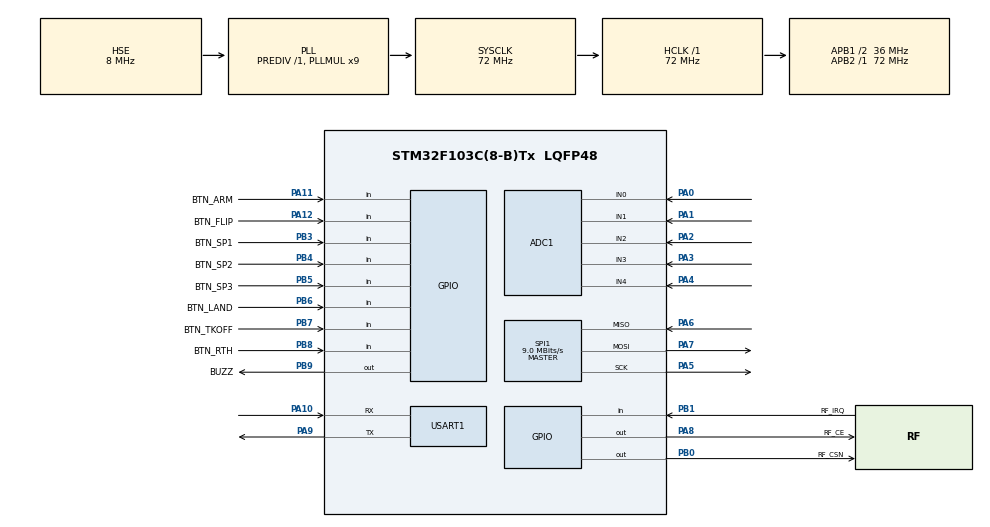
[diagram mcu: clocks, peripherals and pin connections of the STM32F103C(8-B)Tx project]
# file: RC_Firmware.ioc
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ADC1.Channel-0\#ChannelRegularConversion=ADC_CHANNEL_0
ADC1.ContinuousConvMode=ENABLE
ADC1.NbrOfConversionFlag=1
ADC1.Rank-0\#ChannelRegularConversion=1
ADC1.SamplingTime-0\#ChannelRegularConversion=ADC_SAMPLETIME_1CYCLE_5
ADC1.master=1
Dma.ADC1.0.Direction=DMA_PERIPH_TO_MEMORY
Dma.ADC1.0.Instance=DMA1_Channel1
Dma.ADC1.0.MemDataAlignment=DMA_MDATAALIGN_HALFWORD
Dma.ADC1.0.MemInc=DMA_MINC_ENABLE
Dma.ADC1.0.Mode=DMA_NORMAL
Dma.ADC1.0.PeriphDataAlignment=DMA_PDATAALIGN_HALFWORD
Dma.ADC1.0.PeriphInc=DMA_PINC_DISABLE
Dma.ADC1.0.Priority=DMA_PRIORITY_LOW
Dma.Request0=ADC1
Mcu.Family=STM32F1
Mcu.Name=STM32F103C(8-B)Tx
Mcu.Package=LQFP48
NVIC.DMA1_Channel1_IRQn=true\:0\:0\:false\:false\:true\:false\:true\:true
NVIC.PriorityGroup=NVIC_PRIORITYGROUP_4
PA0-WKUP.Signal=ADCx_IN0
PA1.Signal=ADCx_IN1
PA10.Mode=Asynchronous
PA10.Signal=USART1_RX
PA11.GPIO_Label=BTN_ARM
PA11.Signal=GPIO_Input
PA12.GPIO_Label=BTN_FLIP
PA12.Signal=GPIO_Input
PA13.Mode=Serial_Wire
PA13.Signal=SYS_JTMS-SWDIO
PA14.Mode=Serial_Wire
PA14.Signal=SYS_JTCK-SWCLK
PA2.Signal=ADCx_IN2
PA3.Signal=ADCx_IN3
PA4.Signal=ADCx_IN4
PA5.Mode=Full_Duplex_Master
PA5.Signal=SPI1_SCK
PA6.Mode=Full_Duplex_Master
PA6.Signal=SPI1_MISO
PA7.Mode=Full_Duplex_Master
PA7.Signal=SPI1_MOSI
PA8.GPIO_Label=RF_CE
PA8.Signal=GPIO_Output
PA9.Mode=Asynchronous
PA9.Signal=USART1_TX
PB0.GPIO_Label=RF_CSN
PB0.Signal=GPIO_Output
PB1.GPIO_Label=RF_IRQ
PB1.Signal=GPIO_Input
PB3.GPIO_Label=BTN_SP1
PB3.Signal=GPIO_Input
PB4.GPIO_Label=BTN_SP2
PB4.Signal=GPIO_Input
PB5.GPIO_Label=BTN_SP3
PB5.Signal=GPIO_Input
PB6.GPIO_Label=BTN_LAND
PB6.Signal=GPIO_Input
PB7.GPIO_Label=BTN_TKOFF
PB7.Signal=GPIO_Input
PB8.GPIO_Label=BTN_RTH
PB8.Signal=GPIO_Input
PB9.GPIO_Label=BUZZ
PB9.Signal=GPIO_Output
PD0-OSC_IN.Mode=HSE-External-Oscillator
PD0-OSC_IN.Signal=RCC_OSC_IN
PD1-OSC_OUT.Mode=HSE-External-Oscillator
PD1-OSC_OUT.Signal=RCC_OSC_OUT
ProjectManager.HeapSize=0x200
ProjectManager.StackSize=0x400
ProjectManager.TargetToolchain=STM32CubeIDE
RCC.ADCPresc=RCC_ADCPCLK2_DIV6
RCC.AHBFreq_Value=72000000
RCC.APB1CLKDivider=RCC_HCLK_DIV2
RCC.APB1Freq_Value=36000000
RCC.APB1TimFreq_Value=72000000
RCC.APB2Freq_Value=72000000
RCC.APB2TimFreq_Value=72000000
RCC.HCLKFreq_Value=72000000
RCC.PLLMUL=RCC_PLL_MUL9
RCC.PLLSourceVirtual=RCC_PLLSOURCE_HSE
RCC.SYSCLKFreq_VALUE=72000000
RCC.SYSCLKSource=RCC_SYSCLKSOURCE_PLLCLK
RCC.USBFreq_Value=72000000
SH.ADCx_IN0.0=ADC1_IN0,IN0
SH.ADCx_IN1.0=ADC1_IN1,IN1
SH.ADCx_IN2.0=ADC1_IN2,IN2
SH.ADCx_IN3.0=ADC1_IN3,IN3
SH.ADCx_IN4.0=ADC1_IN4,IN4
SPI1.BaudRatePrescaler=SPI_BAUDRATEPRESCALER_8
SPI1.CalculateBaudRate=9.0 MBits/s
SPI1.Direction=SPI_DIRECTION_2LINES
SPI1.Mode=SPI_MODE_MASTER
SPI1.VirtualType=VM_MASTER
USART1.VirtualMode=VM_ASYNC
board=custom

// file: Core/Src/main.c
/* USER CODE BEGIN Header */
/**
  ******************************************************************************
  * @file           : main.c
  * @brief          : Main program body
  ******************************************************************************
  * @attention
  *
  * Copyright (c) 2026 STMicroelectronics.
  * All rights reserved.
  *
  * This software is licensed under terms that can be found in the LICENSE file
  * in the root directory of this software component.
  * If no LICENSE file comes with this software, it is provided AS-IS.
  *
  ******************************************************************************
  */
/* USER CODE END Header */
#include "main.h"

/* USER CODE BEGIN Includes */
#include "bk2423.h"
#include "rc_input.h"
#include "rc_packet.h"
/* USER CODE END Includes */

ADC_HandleTypeDef hadc1;
DMA_HandleTypeDef hdma_adc1;

SPI_HandleTypeDef hspi1;

UART_HandleTypeDef huart1;

/* USER CODE BEGIN PV */
static NRF_Handle nrf = { &hspi1, RF_CE_GPIO_Port, RF_CE_Pin,
                                   RF_CSN_GPIO_Port, RF_CSN_Pin };
static uint16_t   adc_raw[5];   /* DMA fills: [0]=thr [1]=yaw [2]=pit [3]=rol [4]=vbat */
static RC_Packet  pkt;
/* USER CODE END PV */

void SystemClock_Config(void);
static void MX_GPIO_Init(void);
static void MX_DMA_Init(void);
static void MX_ADC1_Init(void);
static void MX_SPI1_Init(void);
static void MX_USART1_UART_Init(void);

int main(void)
{

  /* MCU Configuration--------------------------------------------------------*/

  /* Reset of all peripherals, Initializes the Flash interface and the Systick. */
  HAL_Init();

  /* Configure the system clock */
  SystemClock_Config();

  /* Initialize all configured peripherals */
  MX_GPIO_Init();
  MX_DMA_Init();
  MX_ADC1_Init();
  MX_SPI1_Init();
  MX_USART1_UART_Init();
  /* USER CODE BEGIN 2 */
  HAL_ADC_Start_DMA(&hadc1, (uint32_t*)adc_raw, 5);
  NRF_Init_TX(&nrf);
  /* USER CODE END 2 */

  /* Infinite loop */
  /* USER CODE BEGIN WHILE */
  while (1) {
      RC_Input_Update(&pkt, adc_raw);
      NRF_Send(&nrf, &pkt, sizeof(pkt));
      HAL_Delay(10);   /* 100 Hz transmit rate */
  /* USER CODE END WHILE */
  }

  }
}

void SystemClock_Config(void)
{
  RCC_OscInitTypeDef RCC_OscInitStruct = {0};
  RCC_ClkInitTypeDef RCC_ClkInitStruct = {0};
  RCC_PeriphCLKInitTypeDef PeriphClkInit = {0};

  /** Initializes the RCC Oscillators according to the specified parameters
  * in the RCC_OscInitTypeDef structure.
  */
  RCC_OscInitStruct.OscillatorType = RCC_OSCILLATORTYPE_HSE;
  RCC_OscInitStruct.HSEState = RCC_HSE_ON;
  RCC_OscInitStruct.HSEPredivValue = RCC_HSE_PREDIV_DIV1;
  RCC_OscInitStruct.HSIState = RCC_HSI_ON;
  RCC_OscInitStruct.PLL.PLLState = RCC_PLL_ON;
  RCC_OscInitStruct.PLL.PLLSource = RCC_PLLSOURCE_HSE;
  RCC_OscInitStruct.PLL.PLLMUL = RCC_PLL_MUL9;
  if (HAL_RCC_OscConfig(&RCC_OscInitStruct) != HAL_OK)
  {
    Error_Handler();
  }

  /** Initializes the CPU, AHB and APB buses clocks
  */
  RCC_ClkInitStruct.ClockType = RCC_CLOCKTYPE_HCLK|RCC_CLOCKTYPE_SYSCLK
                              |RCC_CLOCKTYPE_PCLK1|RCC_CLOCKTYPE_PCLK2;
  RCC_ClkInitStruct.SYSCLKSource = RCC_SYSCLKSOURCE_PLLCLK;
  RCC_ClkInitStruct.AHBCLKDivider = RCC_SYSCLK_DIV1;
  RCC_ClkInitStruct.APB1CLKDivider = RCC_HCLK_DIV2;
  RCC_ClkInitStruct.APB2CLKDivider = RCC_HCLK_DIV1;

  if (HAL_RCC_ClockConfig(&RCC_ClkInitStruct, FLASH_LATENCY_2) != HAL_OK)
  {
    Error_Handler();
  }
  PeriphClkInit.PeriphClockSelection = RCC_PERIPHCLK_ADC;
  PeriphClkInit.AdcClockSelection = RCC_ADCPCLK2_DIV6;
  if (HAL_RCCEx_PeriphCLKConfig(&PeriphClkInit) != HAL_OK)
  {
    Error_Handler();
  }
}

static void MX_ADC1_Init(void)
{

  ADC_ChannelConfTypeDef sConfig = {0};

  /** Common config
  */
  hadc1.Instance = ADC1;
  hadc1.Init.ScanConvMode = ADC_SCAN_DISABLE;
  hadc1.Init.ContinuousConvMode = ENABLE;
  hadc1.Init.DiscontinuousConvMode = DISABLE;
  hadc1.Init.ExternalTrigConv = ADC_SOFTWARE_START;
  hadc1.Init.DataAlign = ADC_DATAALIGN_RIGHT;
  hadc1.Init.NbrOfConversion = 1;
  if (HAL_ADC_Init(&hadc1) != HAL_OK)
  {
    Error_Handler();
  }

  /** Configure Regular Channel
  */
  sConfig.Channel = ADC_CHANNEL_0;
  sConfig.Rank = ADC_REGULAR_RANK_1;
  sConfig.SamplingTime = ADC_SAMPLETIME_1CYCLE_5;
  if (HAL_ADC_ConfigChannel(&hadc1, &sConfig) != HAL_OK)
  {
    Error_Handler();
  }

}

static void MX_SPI1_Init(void)
{

  /* SPI1 parameter configuration*/
  hspi1.Instance = SPI1;
  hspi1.Init.Mode = SPI_MODE_MASTER;
  hspi1.Init.Direction = SPI_DIRECTION_2LINES;
  hspi1.Init.DataSize = SPI_DATASIZE_8BIT;
  hspi1.Init.CLKPolarity = SPI_POLARITY_LOW;
  hspi1.Init.CLKPhase = SPI_PHASE_1EDGE;
  hspi1.Init.NSS = SPI_NSS_SOFT;
  hspi1.Init.BaudRatePrescaler = SPI_BAUDRATEPRESCALER_8;
  hspi1.Init.FirstBit = SPI_FIRSTBIT_MSB;
  hspi1.Init.TIMode = SPI_TIMODE_DISABLE;
  hspi1.Init.CRCCalculation = SPI_CRCCALCULATION_DISABLE;
  hspi1.Init.CRCPolynomial = 10;
  if (HAL_SPI_Init(&hspi1) != HAL_OK)
  {
    Error_Handler();
  }

}

static void MX_USART1_UART_Init(void)
{

  huart1.Instance = USART1;
  huart1.Init.BaudRate = 115200;
  huart1.Init.WordLength = UART_WORDLENGTH_8B;
  huart1.Init.StopBits = UART_STOPBITS_1;
  huart1.Init.Parity = UART_PARITY_NONE;
  huart1.Init.Mode = UART_MODE_TX_RX;
  huart1.Init.HwFlowCtl = UART_HWCONTROL_NONE;
  huart1.Init.OverSampling = UART_OVERSAMPLING_16;
  if (HAL_UART_Init(&huart1) != HAL_OK)
  {
    Error_Handler();
  }

}

static void MX_DMA_Init(void)
{

  /* DMA controller clock enable */
  __HAL_RCC_DMA1_CLK_ENABLE();

  /* DMA interrupt init */
  /* DMA1_Channel1_IRQn interrupt configuration */
  HAL_NVIC_SetPriority(DMA1_Channel1_IRQn, 0, 0);
  HAL_NVIC_EnableIRQ(DMA1_Channel1_IRQn);

}

static void MX_GPIO_Init(void)
{
  GPIO_InitTypeDef GPIO_InitStruct = {0};

  /* GPIO Ports Clock Enable */
  __HAL_RCC_GPIOD_CLK_ENABLE();
  __HAL_RCC_GPIOA_CLK_ENABLE();
  __HAL_RCC_GPIOB_CLK_ENABLE();

  /*Configure GPIO pin Output Level */
  HAL_GPIO_WritePin(GPIOB, RF_CSN_Pin|BUZZ_Pin, GPIO_PIN_RESET);

  /*Configure GPIO pin Output Level */
  HAL_GPIO_WritePin(RF_CE_GPIO_Port, RF_CE_Pin, GPIO_PIN_RESET);

  /*Configure GPIO pins : RF_CSN_Pin BUZZ_Pin */
  GPIO_InitStruct.Pin = RF_CSN_Pin|BUZZ_Pin;
  GPIO_InitStruct.Mode = GPIO_MODE_OUTPUT_PP;
  GPIO_InitStruct.Pull = GPIO_NOPULL;
  GPIO_InitStruct.Speed = GPIO_SPEED_FREQ_LOW;
  HAL_GPIO_Init(GPIOB, &GPIO_InitStruct);

  /*Configure GPIO pins : RF_IRQ_Pin BTN_SP1_Pin BTN_SP2_Pin BTN_SP3_Pin
                           BTN_LAND_Pin BTN_TKOFF_Pin BTN_RTH_Pin */
  GPIO_InitStruct.Pin = RF_IRQ_Pin|BTN_SP1_Pin|BTN_SP2_Pin|BTN_SP3_Pin
                          |BTN_LAND_Pin|BTN_TKOFF_Pin|BTN_RTH_Pin;
  GPIO_InitStruct.Mode = GPIO_MODE_INPUT;
  GPIO_InitStruct.Pull = GPIO_NOPULL;
  HAL_GPIO_Init(GPIOB, &GPIO_InitStruct);

  /*Configure GPIO pin : RF_CE_Pin */
  GPIO_InitStruct.Pin = RF_CE_Pin;
  GPIO_InitStruct.Mode = GPIO_MODE_OUTPUT_PP;
  GPIO_InitStruct.Pull = GPIO_NOPULL;
  GPIO_InitStruct.Speed = GPIO_SPEED_FREQ_LOW;
  HAL_GPIO_Init(RF_CE_GPIO_Port, &GPIO_InitStruct);

  /*Configure GPIO pins : BTN_ARM_Pin BTN_FLIP_Pin */
  GPIO_InitStruct.Pin = BTN_ARM_Pin|BTN_FLIP_Pin;
  GPIO_InitStruct.Mode = GPIO_MODE_INPUT;
  GPIO_InitStruct.Pull = GPIO_NOPULL;
  HAL_GPIO_Init(GPIOA, &GPIO_InitStruct);

}

void Error_Handler(void)
{
  __disable_irq();
  while (1)
  {
  }
}
